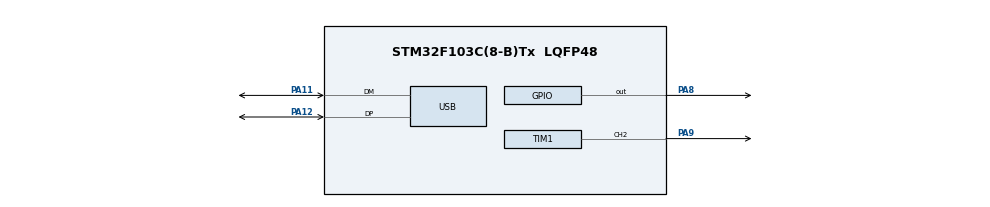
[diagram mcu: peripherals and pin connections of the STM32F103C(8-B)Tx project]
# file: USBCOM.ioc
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Mcu.Family=STM32F1
Mcu.Name=STM32F103C(8-B)Tx
Mcu.Package=LQFP48
NVIC.PriorityGroup=NVIC_PRIORITYGROUP_4
NVIC.TIM1_UP_IRQn=true\:0\:0\:false\:false\:true\:true\:true\:true
NVIC.USB_LP_CAN1_RX0_IRQn=true\:0\:0\:false\:false\:true\:false\:true\:true
PA11.Mode=Device
PA11.Signal=USB_DM
PA12.Mode=Device
PA12.Signal=USB_DP
PA13.Mode=Trace_Asynchronous_SW
PA13.Signal=SYS_JTMS-SWDIO
PA14.Mode=Trace_Asynchronous_SW
PA14.Signal=SYS_JTCK-SWCLK
PA8.GPIO_ModeDefaultOutputPP=GPIO_MODE_OUTPUT_OD
PA8.GPIO_PuPd=GPIO_NOPULL
PA8.PinState=GPIO_PIN_SET
PA8.Signal=GPIO_Output
PA9.Signal=S_TIM1_CH2
PB3.Mode=Trace_Asynchronous_SW
PB3.Signal=SYS_JTDO-TRACESWO
PD0-OSC_IN.Mode=HSE-External-Oscillator
PD0-OSC_IN.Signal=RCC_OSC_IN
PD1-OSC_OUT.Mode=HSE-External-Oscillator
PD1-OSC_OUT.Signal=RCC_OSC_OUT
ProjectManager.HeapSize=0x200
ProjectManager.StackSize=0x400
ProjectManager.TargetToolchain=EWARM V8
RCC.AHBFreq_Value=48000000
RCC.APB1CLKDivider=RCC_HCLK_DIV2
RCC.APB1Freq_Value=24000000
RCC.APB1TimFreq_Value=48000000
RCC.APB2Freq_Value=48000000
RCC.APB2TimFreq_Value=48000000
RCC.HCLKFreq_Value=48000000
RCC.PLLMUL=RCC_PLL_MUL6
RCC.PLLSourceVirtual=RCC_PLLSOURCE_HSE
RCC.SYSCLKFreq_VALUE=48000000
RCC.SYSCLKSource=RCC_SYSCLKSOURCE_PLLCLK
RCC.USBFreq_Value=48000000
SH.S_TIM1_CH2.0=TIM1_CH2,Output Compare2 CH2
TIM1.Channel-Output\ Compare2\ CH2=TIM_CHANNEL_2
USB_DEVICE.CLASS_NAME_FS=CDC
USB_DEVICE.VirtualMode=Cdc
USB_DEVICE.VirtualModeFS=Cdc_FS
VP_TIM1_VS_ClockSourceINT.Mode=Internal
VP_USB_DEVICE_VS_USB_DEVICE_CDC_FS.Mode=CDC_FS
board=custom

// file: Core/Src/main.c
/* USER CODE BEGIN Header */
/**
  ******************************************************************************
  * @file           : main.c
  * @brief          : Main program body
  ******************************************************************************
  * @attention
  *
  * Copyright (c) 2022 STMicroelectronics.
  * All rights reserved.
  *
  * This software is licensed under terms that can be found in the LICENSE file
  * in the root directory of this software component.
  * If no LICENSE file comes with this software, it is provided AS-IS.
  *
  ******************************************************************************
  */
/* USER CODE END Header */
#include "main.h"
#include "usb_device.h"
#include "usbd_cdc_if.h"
#include "mc_model.h"
#include "mc_cli.h"

void SystemClock_Config(void);
static void MX_GPIO_Init(void);
static void MX_TIM1_Init(void);

int main(void)
{

  /* MCU Configuration--------------------------------------------------------*/

  /* Reset of all peripherals, Initializes the Flash interface and the Systick. */
  HAL_Init();

  /* Configure the system clock */
  SystemClock_Config();

  /* Initialize all configured peripherals */
  MX_GPIO_Init();
  MX_TIM1_Init();
  MX_USB_DEVICE_Init();
//  MX_SPI1_Init();
//  MX_I2C1_Init();

  /* USER CODE BEGIN 2 */
  mc_model_init(NULL);
  mci_cli_init(NULL);
  /* USER CODE END 2 */

  /* Infinite loop */
  while (1)
  {
    mci_cli_process_comand();
  }
}

void SystemClock_Config(void)
{
  LL_FLASH_SetLatency(LL_FLASH_LATENCY_1);
  while(LL_FLASH_GetLatency()!= LL_FLASH_LATENCY_1)
  {
  }
  LL_RCC_HSE_Enable();

   /* Wait till HSE is ready */
  while(LL_RCC_HSE_IsReady() != 1)
  {

  }
  LL_RCC_PLL_ConfigDomain_SYS(LL_RCC_PLLSOURCE_HSE_DIV_1, LL_RCC_PLL_MUL_6);
  LL_RCC_PLL_Enable();

   /* Wait till PLL is ready */
  while(LL_RCC_PLL_IsReady() != 1)
  {

  }
  LL_RCC_SetAHBPrescaler(LL_RCC_SYSCLK_DIV_1);
  LL_RCC_SetAPB1Prescaler(LL_RCC_APB1_DIV_2);
  LL_RCC_SetAPB2Prescaler(LL_RCC_APB2_DIV_1);
  LL_RCC_SetSysClkSource(LL_RCC_SYS_CLKSOURCE_PLL);

   /* Wait till System clock is ready */
  while(LL_RCC_GetSysClkSource() != LL_RCC_SYS_CLKSOURCE_STATUS_PLL)
  {

  }
  LL_SetSystemCoreClock(48000000);

   /* Update the time base */
  if (HAL_InitTick (TICK_INT_PRIORITY) != HAL_OK)
  {
    Error_Handler();
  }
  LL_RCC_SetUSBClockSource(LL_RCC_USB_CLKSOURCE_PLL);
}

static void MX_TIM1_Init(void)
{

  LL_TIM_InitTypeDef TIM_InitStruct = {0};
  LL_TIM_OC_InitTypeDef TIM_OC_InitStruct = {0};
  LL_TIM_BDTR_InitTypeDef TIM_BDTRInitStruct = {0};

  LL_GPIO_InitTypeDef GPIO_InitStruct = {0};

  /* Peripheral clock enable */
  LL_APB2_GRP1_EnableClock(LL_APB2_GRP1_PERIPH_TIM1);

  /* TIM1 interrupt Init */
  //NVIC_SetPriority(TIM1_UP_IRQn, NVIC_EncodePriority(NVIC_GetPriorityGrouping(),0, 0));
  //NVIC_EnableIRQ(TIM1_UP_IRQn);

  TIM_InitStruct.Prescaler = 10;
  TIM_InitStruct.CounterMode = LL_TIM_COUNTERMODE_UP;
  TIM_InitStruct.Autoreload = 47;
  TIM_InitStruct.ClockDivision = LL_TIM_CLOCKDIVISION_DIV1;
  TIM_InitStruct.RepetitionCounter = 0;
  LL_TIM_Init(TIM1, &TIM_InitStruct);
  LL_TIM_DisableARRPreload(TIM1);
  LL_TIM_SetClockSource(TIM1, LL_TIM_CLOCKSOURCE_INTERNAL);
  TIM_OC_InitStruct.OCMode = LL_TIM_OCMODE_FROZEN;
  TIM_OC_InitStruct.OCState = LL_TIM_OCSTATE_DISABLE;
  TIM_OC_InitStruct.OCNState = LL_TIM_OCSTATE_DISABLE;
  TIM_OC_InitStruct.CompareValue = 0;
  TIM_OC_InitStruct.OCPolarity = LL_TIM_OCPOLARITY_HIGH;
  TIM_OC_InitStruct.OCNPolarity = LL_TIM_OCPOLARITY_HIGH;
  TIM_OC_InitStruct.OCIdleState = LL_TIM_OCIDLESTATE_LOW;
  TIM_OC_InitStruct.OCNIdleState = LL_TIM_OCIDLESTATE_LOW;
  LL_TIM_OC_Init(TIM1, LL_TIM_CHANNEL_CH2, &TIM_OC_InitStruct);
  LL_TIM_OC_DisableFast(TIM1, LL_TIM_CHANNEL_CH2);
  LL_TIM_SetTriggerOutput(TIM1, LL_TIM_TRGO_RESET);
  LL_TIM_DisableMasterSlaveMode(TIM1);
  TIM_BDTRInitStruct.OSSRState = LL_TIM_OSSR_DISABLE;
  TIM_BDTRInitStruct.OSSIState = LL_TIM_OSSI_DISABLE;
  TIM_BDTRInitStruct.LockLevel = LL_TIM_LOCKLEVEL_OFF;
  TIM_BDTRInitStruct.DeadTime = 0;
  TIM_BDTRInitStruct.BreakState = LL_TIM_BREAK_DISABLE;
  TIM_BDTRInitStruct.BreakPolarity = LL_TIM_BREAK_POLARITY_HIGH;
  TIM_BDTRInitStruct.AutomaticOutput = LL_TIM_AUTOMATICOUTPUT_DISABLE;
  LL_TIM_BDTR_Init(TIM1, &TIM_BDTRInitStruct);
  LL_APB2_GRP1_EnableClock(LL_APB2_GRP1_PERIPH_GPIOA);
  /**TIM1 GPIO Configuration
  PA9   ------> TIM1_CH2
  */
  GPIO_InitStruct.Pin = LL_GPIO_PIN_9;
  GPIO_InitStruct.Mode = LL_GPIO_MODE_ALTERNATE;
  GPIO_InitStruct.Speed = LL_GPIO_SPEED_FREQ_LOW;
  GPIO_InitStruct.OutputType = LL_GPIO_OUTPUT_PUSHPULL;
  LL_GPIO_Init(GPIOA, &GPIO_InitStruct);

}

static void MX_GPIO_Init(void)
{
  LL_GPIO_InitTypeDef GPIO_InitStruct = {0};

  /* GPIO Ports Clock Enable */
  LL_APB2_GRP1_EnableClock(LL_APB2_GRP1_PERIPH_GPIOD);
  LL_APB2_GRP1_EnableClock(LL_APB2_GRP1_PERIPH_GPIOA);
  LL_APB2_GRP1_EnableClock(LL_APB2_GRP1_PERIPH_GPIOB);

  /**/
  LL_GPIO_SetOutputPin(GPIOA, LL_GPIO_PIN_8);

  /**/
  GPIO_InitStruct.Pin = LL_GPIO_PIN_8;
  GPIO_InitStruct.Mode = LL_GPIO_MODE_OUTPUT;
  GPIO_InitStruct.Speed = LL_GPIO_SPEED_FREQ_LOW;
  GPIO_InitStruct.OutputType = LL_GPIO_OUTPUT_OPENDRAIN;
  LL_GPIO_Init(GPIOA, &GPIO_InitStruct);

}

void Error_Handler(void)
{
  __disable_irq();
  while (1)
  {
  }
}
